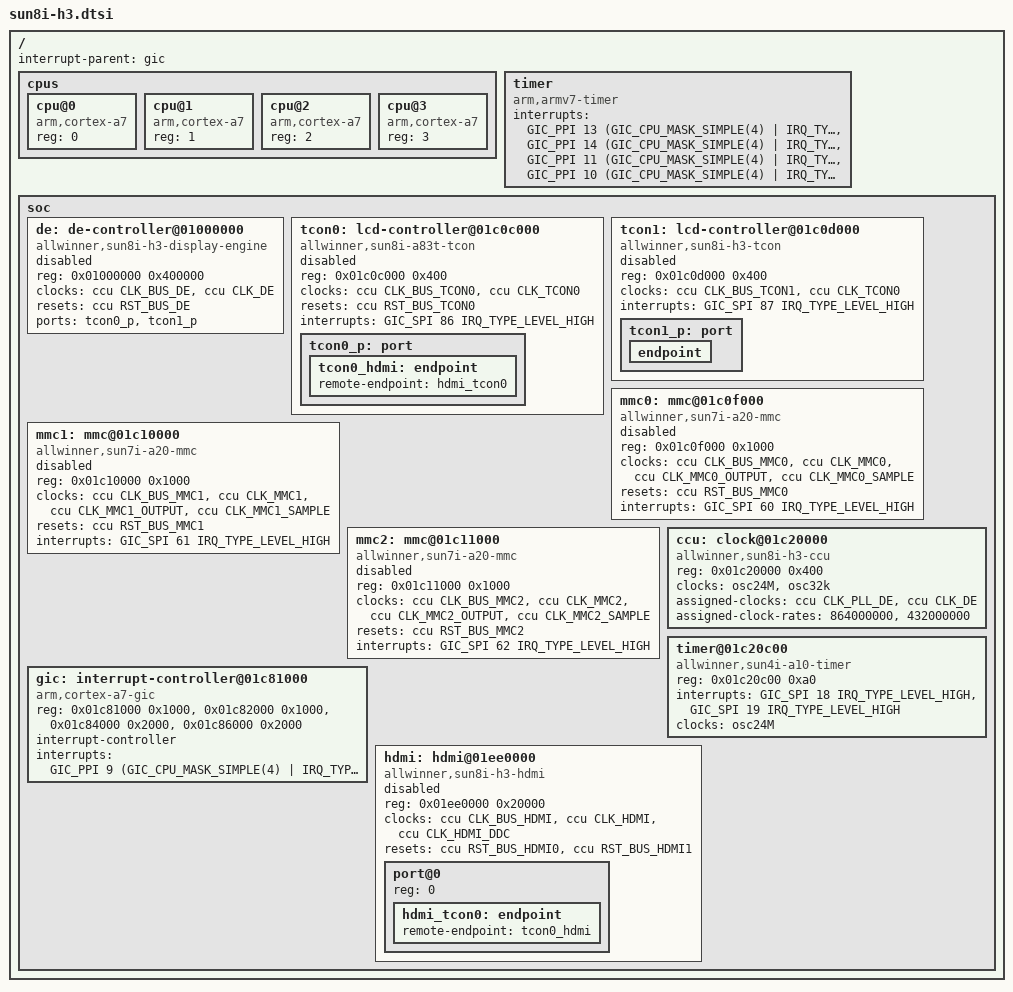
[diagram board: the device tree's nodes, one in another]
/*
 * Copyright (C) 2015 Jens Kuske <jenskuske@gmail.com>
 *
 * This file is dual-licensed: you can use it either under the terms
 * of the GPL or the X11 license, at your option. Note that this dual
 * licensing only applies to this file, and not this project as a
 * whole.
 *
 *  a) This file is free software; you can redistribute it and/or
 *     modify it under the terms of the GNU General Public License as
 *     published by the Free Software Foundation; either version 2 of the
 *     License, or (at your option) any later version.
 *
 *     This file is distributed in the hope that it will be useful,
 *     but WITHOUT ANY WARRANTY; without even the implied warranty of
 *     MERCHANTABILITY or FITNESS FOR A PARTICULAR PURPOSE.  See the
 *     GNU General Public License for more details.
 *
 * Or, alternatively,
 *
 *  b) Permission is hereby granted, free of charge, to any person
 *     obtaining a copy of this software and associated documentation
 *     files (the "Software"), to deal in the Software without
 *     restriction, including without limitation the rights to use,
 *     copy, modify, merge, publish, distribute, sublicense, and/or
 *     sell copies of the Software, and to permit persons to whom the
 *     Software is furnished to do so, subject to the following
 *     conditions:
 *
 *     The above copyright notice and this permission notice shall be
 *     included in all copies or substantial portions of the Software.
 *
 *     THE SOFTWARE IS PROVIDED "AS IS", WITHOUT WARRANTY OF ANY KIND,
 *     EXPRESS OR IMPLIED, INCLUDING BUT NOT LIMITED TO THE WARRANTIES
 *     OF MERCHANTABILITY, FITNESS FOR A PARTICULAR PURPOSE AND
 *     NONINFRINGEMENT. IN NO EVENT SHALL THE AUTHORS OR COPYRIGHT
 *     HOLDERS BE LIABLE FOR ANY CLAIM, DAMAGES OR OTHER LIABILITY,
 *     WHETHER IN AN ACTION OF CONTRACT, TORT OR OTHERWISE, ARISING
 *     FROM, OUT OF OR IN CONNECTION WITH THE SOFTWARE OR THE USE OR
 *     OTHER DEALINGS IN THE SOFTWARE.
 */

#include "sun8i-h3-h5.dtsi"

/ {
	interrupt-parent = <&gic>;

	cpus {
		#address-cells = <1>;
		#size-cells = <0>;

		cpu@0 {
			compatible = "arm,cortex-a7";
			device_type = "cpu";
			reg = <0>;
		};

		cpu@1 {
			compatible = "arm,cortex-a7";
			device_type = "cpu";
			reg = <1>;
		};

		cpu@2 {
			compatible = "arm,cortex-a7";
			device_type = "cpu";
			reg = <2>;
		};

		cpu@3 {
			compatible = "arm,cortex-a7";
			device_type = "cpu";
			reg = <3>;
		};
	};

	timer {
		compatible = "arm,armv7-timer";
		interrupts = <GIC_PPI 13 (GIC_CPU_MASK_SIMPLE(4) | IRQ_TYPE_LEVEL_LOW)>,
			     <GIC_PPI 14 (GIC_CPU_MASK_SIMPLE(4) | IRQ_TYPE_LEVEL_LOW)>,
			     <GIC_PPI 11 (GIC_CPU_MASK_SIMPLE(4) | IRQ_TYPE_LEVEL_LOW)>,
			     <GIC_PPI 10 (GIC_CPU_MASK_SIMPLE(4) | IRQ_TYPE_LEVEL_LOW)>;
	};

	soc {
		de: de-controller@01000000 {
			compatible = "allwinner,sun8i-h3-display-engine";
			reg = <0x01000000 0x400000>;
			clocks = <&ccu CLK_BUS_DE>, <&ccu CLK_DE>;
			clock-names = "bus", "clock";
			resets = <&ccu RST_BUS_DE>;
			ports = <&tcon0_p>, <&tcon1_p>;
			status = "disabled";
		};

		tcon0: lcd-controller@01c0c000 {
			compatible = "allwinner,sun8i-a83t-tcon";
			reg = <0x01c0c000 0x400>;
			clocks = <&ccu CLK_BUS_TCON0>, <&ccu CLK_TCON0>;
			clock-names = "bus", "clock";
			resets = <&ccu RST_BUS_TCON0>;
			interrupts = <GIC_SPI 86 IRQ_TYPE_LEVEL_HIGH>;
			status = "disabled";
			tcon0_p: port {
				tcon0_hdmi: endpoint {
					remote-endpoint = <&hdmi_tcon0>;
				};
			};
		};

		/* not used */
		tcon1: lcd-controller@01c0d000 {
			compatible = "allwinner,sun8i-h3-tcon";
			reg = <0x01c0d000 0x400>;
			clocks = <&ccu CLK_BUS_TCON1>,
				 <&ccu CLK_TCON0>;      /* no clock */
			clock-names = "bus", "clock";
			interrupts = <GIC_SPI 87 IRQ_TYPE_LEVEL_HIGH>;
			status = "disabled";
			tcon1_p: port {
				endpoint {
					/* empty */
				};
			};
		};

		mmc0: mmc@01c0f000 {
			compatible = "allwinner,sun7i-a20-mmc";
			reg = <0x01c0f000 0x1000>;
			clocks = <&ccu CLK_BUS_MMC0>,
				 <&ccu CLK_MMC0>,
				 <&ccu CLK_MMC0_OUTPUT>,
				 <&ccu CLK_MMC0_SAMPLE>;
			clock-names = "ahb",
				      "mmc",
				      "output",
				      "sample";
			resets = <&ccu RST_BUS_MMC0>;
			reset-names = "ahb";
			interrupts = <GIC_SPI 60 IRQ_TYPE_LEVEL_HIGH>;
			status = "disabled";
			#address-cells = <1>;
			#size-cells = <0>;
		};

		mmc1: mmc@01c10000 {
			compatible = "allwinner,sun7i-a20-mmc";
			reg = <0x01c10000 0x1000>;
			clocks = <&ccu CLK_BUS_MMC1>,
				 <&ccu CLK_MMC1>,
				 <&ccu CLK_MMC1_OUTPUT>,
				 <&ccu CLK_MMC1_SAMPLE>;
			clock-names = "ahb",
				      "mmc",
				      "output",
				      "sample";
			resets = <&ccu RST_BUS_MMC1>;
			reset-names = "ahb";
			interrupts = <GIC_SPI 61 IRQ_TYPE_LEVEL_HIGH>;
			status = "disabled";
			#address-cells = <1>;
			#size-cells = <0>;
		};

		mmc2: mmc@01c11000 {
			compatible = "allwinner,sun7i-a20-mmc";
			reg = <0x01c11000 0x1000>;
			clocks = <&ccu CLK_BUS_MMC2>,
				 <&ccu CLK_MMC2>,
				 <&ccu CLK_MMC2_OUTPUT>,
				 <&ccu CLK_MMC2_SAMPLE>;
			clock-names = "ahb",
				      "mmc",
				      "output",
				      "sample";
			resets = <&ccu RST_BUS_MMC2>;
			reset-names = "ahb";
			interrupts = <GIC_SPI 62 IRQ_TYPE_LEVEL_HIGH>;
			status = "disabled";
			#address-cells = <1>;
			#size-cells = <0>;
		};

		ccu: clock@01c20000 {
			compatible = "allwinner,sun8i-h3-ccu";
			reg = <0x01c20000 0x400>;
			clocks = <&osc24M>, <&osc32k>;
			clock-names = "hosc", "losc";
			#clock-cells = <1>;
			#reset-cells = <1>;

			assigned-clocks = <&ccu CLK_PLL_DE>,
					  <&ccu CLK_DE>;
			assigned-clock-rates =  <864000000>,
						<432000000>;
		};

		timer@01c20c00 {
			compatible = "allwinner,sun4i-a10-timer";
			reg = <0x01c20c00 0xa0>;
			interrupts = <GIC_SPI 18 IRQ_TYPE_LEVEL_HIGH>,
				     <GIC_SPI 19 IRQ_TYPE_LEVEL_HIGH>;
			clocks = <&osc24M>;
		};

		gic: interrupt-controller@01c81000 {
			compatible = "arm,cortex-a7-gic", "arm,cortex-a15-gic";
			reg = <0x01c81000 0x1000>,
			      <0x01c82000 0x1000>,
			      <0x01c84000 0x2000>,
			      <0x01c86000 0x2000>;
			interrupt-controller;
			#interrupt-cells = <3>;
			interrupts = <GIC_PPI 9 (GIC_CPU_MASK_SIMPLE(4) | IRQ_TYPE_LEVEL_HIGH)>;
		};

		hdmi: hdmi@01ee0000 {
			compatible = "allwinner,sun8i-h3-hdmi";
			reg = <0x01ee0000 0x20000>;
			clocks = <&ccu CLK_BUS_HDMI>, <&ccu CLK_HDMI>,
				 <&ccu CLK_HDMI_DDC>;
			clock-names = "bus", "clock", "ddc-clock";
			resets = <&ccu RST_BUS_HDMI0>, <&ccu RST_BUS_HDMI1>;
			reset-names = "hdmi0", "hdmi1";
			status = "disabled";
			#address-cells = <1>;
			#size-cells = <0>;
			port@0 {			/* video */
				reg = <0>;
				hdmi_tcon0: endpoint {
					remote-endpoint = <&tcon0_hdmi>;
				};
			};
		};
	};
};
